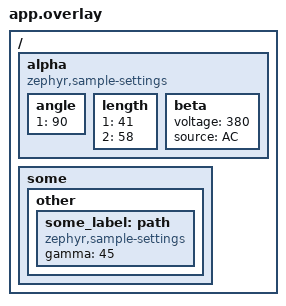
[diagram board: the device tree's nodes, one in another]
/* SPDX-License-Identifier: Apache-2.0 */

/*
 * Sample NVS settings provisioning configuration.
 */

/{
	alpha {
		compatible = "zephyr,sample-settings";

		angle {
			1 = <90>;
		};

		length {
			1 = <41>;
			2 = <58>;
		};

		beta {
			voltage = <380>;
			source = "AC";
		};
	};

	some {
		other {
			some_label: path {
				compatible = "zephyr,sample-settings";

				gamma = <45>;
			};
		};
	};
};
